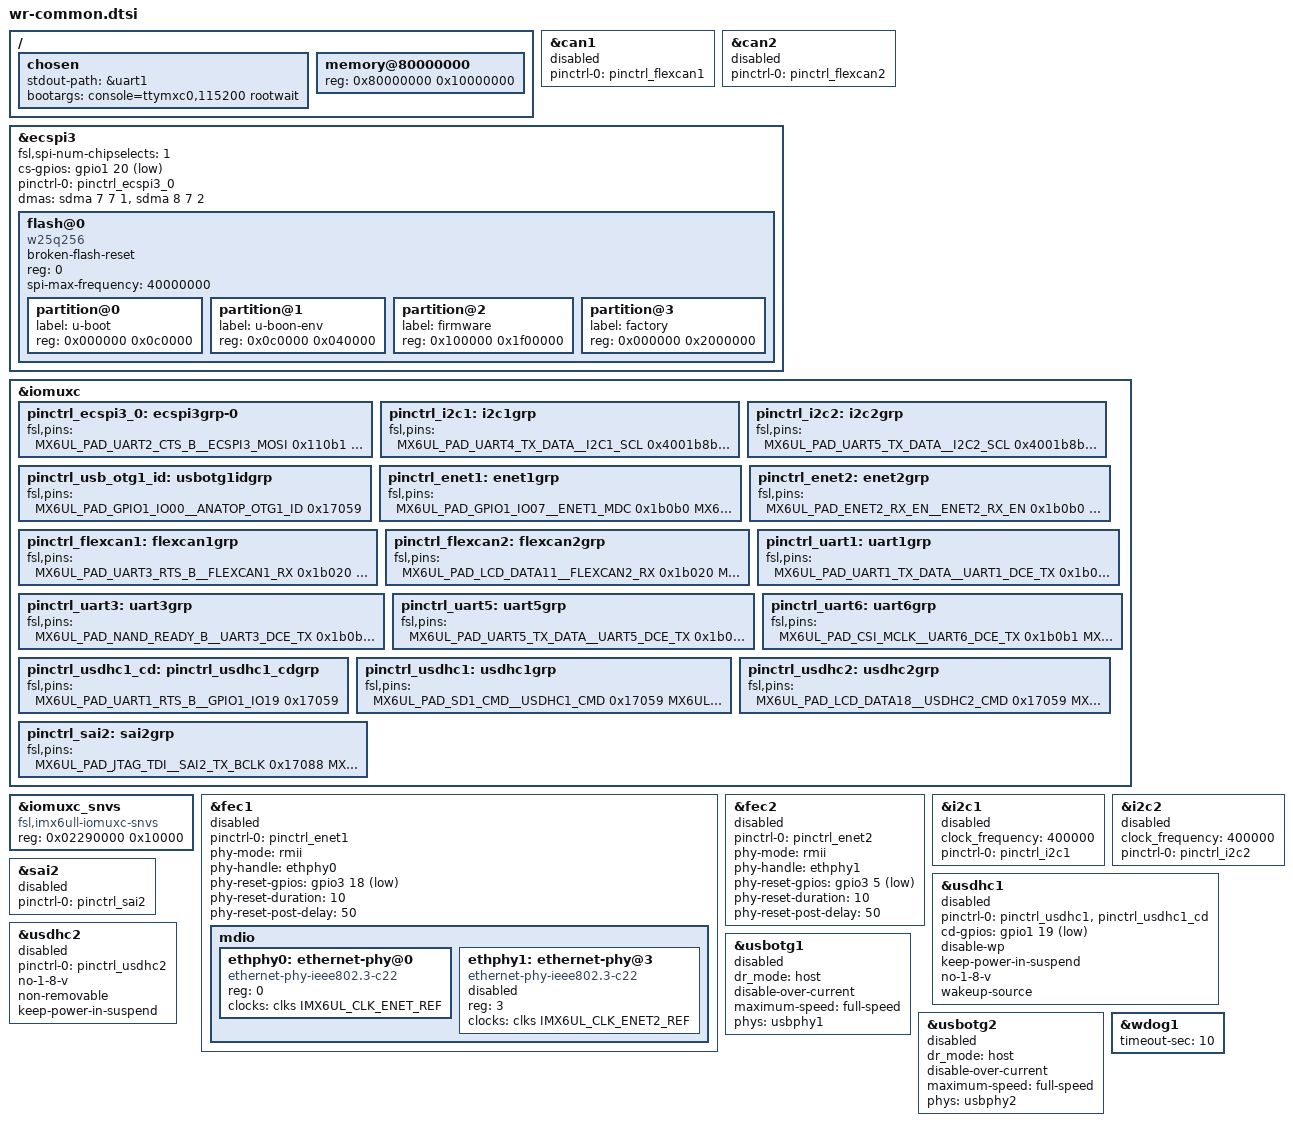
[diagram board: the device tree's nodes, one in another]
// SPDX-License-Identifier: GPL-2.0-only
/*
 * Device Tree Source for WirelessRoad Boards
 */


#include <dt-bindings/input/input.h>
#include "imx6ull.dtsi"

/ {
    chosen {
		stdout-path = &uart1;
		bootargs = "console=ttymxc0,115200 rootwait";
	};

    memory@80000000 {
        device_type = "memory";
		reg = <0x80000000 0x10000000>;
	};
};

&can1 {
	pinctrl-names = "default";
	pinctrl-0 = <&pinctrl_flexcan1>;
	status = "disabled";
};

&can2 {
	pinctrl-names = "default";
	pinctrl-0 = <&pinctrl_flexcan2>;
	status = "disabled";
};

// Do we really need this?
// &clks {
// 	assigned-clocks = <&clks IMX6UL_CLK_PLL4_AUDIO_DIV>;
// 	assigned-clock-rates = <786432000>;
// };

&ecspi3 {
	fsl,spi-num-chipselects = <1>;
	cs-gpios = <&gpio1 20 GPIO_ACTIVE_LOW>;
	pinctrl-names = "default";
	pinctrl-0 = <&pinctrl_ecspi3_0>;
	status = "okay";
	dma-names = "rx", "tx";
	dmas = <&sdma 7 7 1>, <&sdma 8 7 2>;

	flash@0 {
		#address-cells = <1>;
		#size-cells = <1>;
		compatible = "w25q256", "jedec,spi-nor";
		broken-flash-reset;
		reg = <0>;
		spi-max-frequency = <40000000>;
		status = "okay";

		partition@0 {
			label = "u-boot";
			reg = <0x000000 0x0c0000>;
		};

		partition@1 {
			label = "u-boon-env";
			reg = <0x0c0000 0x040000>;
		};

		partition@2 {
			label = "firmware";
			reg = <0x100000 0x1f00000>;
		};

		partition@3 {
			label = "factory";
			reg = <0x000000 0x2000000>;
		};
	};
};

&iomuxc {
	pinctrl_ecspi3_0: ecspi3grp-0 {
		fsl,pins = <
			MX6UL_PAD_UART2_CTS_B__ECSPI3_MOSI	0x110b1
			MX6UL_PAD_UART2_RTS_B__ECSPI3_MISO	0x110b1
			MX6UL_PAD_UART2_RX_DATA__ECSPI3_SCLK	0x110b1
			MX6UL_PAD_UART2_TX_DATA__GPIO1_IO20	0x10b0
		>;
	};

	pinctrl_i2c1: i2c1grp {
		fsl,pins = <
			MX6UL_PAD_UART4_TX_DATA__I2C1_SCL	0x4001b8b0
			MX6UL_PAD_UART4_RX_DATA__I2C1_SDA	0x4001b8b0
		>;
	};

	pinctrl_i2c2: i2c2grp {
		fsl,pins = <
			MX6UL_PAD_UART5_TX_DATA__I2C2_SCL		0x4001b8b0
			MX6UL_PAD_UART5_RX_DATA__I2C2_SDA		0x4001b8b0
		>;
	};

	pinctrl_usb_otg1_id: usbotg1idgrp {
		fsl,pins = <
			MX6UL_PAD_GPIO1_IO00__ANATOP_OTG1_ID	0x17059
		>;
	};
	
	pinctrl_enet1: enet1grp {
		fsl,pins = <
			MX6UL_PAD_GPIO1_IO07__ENET1_MDC         0x1b0b0
			MX6UL_PAD_GPIO1_IO06__ENET1_MDIO	0x1b0b0
			MX6UL_PAD_ENET1_RX_EN__ENET1_RX_EN	0x1b0b0
			MX6UL_PAD_ENET1_RX_ER__ENET1_RX_ER	0x1b0b0
			MX6UL_PAD_ENET1_RX_DATA0__ENET1_RDATA00	0x1b0b0
			MX6UL_PAD_ENET1_RX_DATA1__ENET1_RDATA01	0x1b0b0
			MX6UL_PAD_ENET1_TX_EN__ENET1_TX_EN	0x1b0b0
			MX6UL_PAD_ENET1_TX_DATA0__ENET1_TDATA00	0x1b0b0
			MX6UL_PAD_ENET1_TX_DATA1__ENET1_TDATA01	0x1b0b0
			MX6UL_PAD_ENET1_TX_CLK__ENET1_REF_CLK1	0x4001b031
		>;
	};

	pinctrl_enet2: enet2grp {
		fsl,pins = <
			MX6UL_PAD_ENET2_RX_EN__ENET2_RX_EN      0x1b0b0
			MX6UL_PAD_ENET2_RX_ER__ENET2_RX_ER      0x1b0b0
			MX6UL_PAD_ENET2_RX_DATA0__ENET2_RDATA00 0x1b0b0
			MX6UL_PAD_ENET2_RX_DATA1__ENET2_RDATA01 0x1b0b0
			MX6UL_PAD_ENET2_TX_EN__ENET2_TX_EN      0x1b0b0
			MX6UL_PAD_ENET2_TX_DATA0__ENET2_TDATA00 0x1b0b0
			MX6UL_PAD_ENET2_TX_DATA1__ENET2_TDATA01 0x1b0b0
			MX6UL_PAD_ENET2_TX_CLK__ENET2_REF_CLK2  0x4001b031
		>;
	};

	pinctrl_flexcan1: flexcan1grp{
		fsl,pins = <
			MX6UL_PAD_UART3_RTS_B__FLEXCAN1_RX	0x1b020
			MX6UL_PAD_UART3_CTS_B__FLEXCAN1_TX	0x1b020
		>;
	};

	pinctrl_flexcan2: flexcan2grp{
		fsl,pins = <
			MX6UL_PAD_LCD_DATA11__FLEXCAN2_RX      0x1b020
			MX6UL_PAD_LCD_DATA10__FLEXCAN2_TX      0x1b020
		>;
	};

	pinctrl_uart1: uart1grp {
		fsl,pins = <
			MX6UL_PAD_UART1_TX_DATA__UART1_DCE_TX 0x1b0b1
			MX6UL_PAD_UART1_RX_DATA__UART1_DCE_RX 0x1b0b1
		>;
	};

	pinctrl_uart3: uart3grp {
		fsl,pins = <
			MX6UL_PAD_NAND_READY_B__UART3_DCE_TX 0x1b0b1
			MX6UL_PAD_NAND_CE0_B__UART3_DCE_RX   0x1b0b1
		>;
	};

	pinctrl_uart5: uart5grp {
		fsl,pins = <
			MX6UL_PAD_UART5_TX_DATA__UART5_DCE_TX 0x1b0b1
			MX6UL_PAD_UART5_RX_DATA__UART5_DCE_RX 0x1b0b1
		>;
	};

	pinctrl_uart6: uart6grp {
		fsl,pins = <
			MX6UL_PAD_CSI_MCLK__UART6_DCE_TX   0x1b0b1
			MX6UL_PAD_CSI_PIXCLK__UART6_DCE_RX 0x1b0b1
		>;
	};

	pinctrl_usdhc1_cd: pinctrl_usdhc1_cdgrp {
		fsl,pins = <
			MX6UL_PAD_UART1_RTS_B__GPIO1_IO19	0x17059 /* SD1 CD */
		>;
	};

	pinctrl_usdhc1: usdhc1grp {
		fsl,pins = <
			MX6UL_PAD_SD1_CMD__USDHC1_CMD		0x17059
			MX6UL_PAD_SD1_CLK__USDHC1_CLK		0x10071
			MX6UL_PAD_SD1_DATA0__USDHC1_DATA0	0x17059
			MX6UL_PAD_SD1_DATA1__USDHC1_DATA1	0x17059
			MX6UL_PAD_SD1_DATA2__USDHC1_DATA2	0x17059
			MX6UL_PAD_SD1_DATA3__USDHC1_DATA3	0x17059
		>;
	};
	
	pinctrl_usdhc2: usdhc2grp {
		fsl,pins = <
			MX6UL_PAD_LCD_DATA18__USDHC2_CMD        0x17059
			MX6UL_PAD_LCD_DATA19__USDHC2_CLK        0x10071
			MX6UL_PAD_LCD_DATA20__USDHC2_DATA0      0x17059
			MX6UL_PAD_LCD_DATA21__USDHC2_DATA1      0x17059
			MX6UL_PAD_LCD_DATA22__USDHC2_DATA2      0x17059
			MX6UL_PAD_LCD_DATA23__USDHC2_DATA3      0x17059
		>;
	};

	pinctrl_sai2: sai2grp {
		fsl,pins = <
			MX6UL_PAD_JTAG_TDI__SAI2_TX_BCLK    0x17088
			MX6UL_PAD_JTAG_TDO__SAI2_TX_SYNC    0x17088
			MX6UL_PAD_JTAG_TRST_B__SAI2_TX_DATA 0x11088
			MX6UL_PAD_JTAG_TCK__SAI2_RX_DATA    0x11088
			MX6UL_PAD_JTAG_TMS__SAI2_MCLK       0x17088
		>;
	};
};

&iomuxc_snvs {
	compatible = "fsl,imx6ull-iomuxc-snvs";
	reg = <0x02290000 0x10000>;
	pinctrl-names = "default_snvs";
};

&fec1 {
	pinctrl-names = "default";
	pinctrl-0 = <&pinctrl_enet1>;
	phy-mode = "rmii";
	phy-handle = <&ethphy0>;
	phy-reset-gpios = <&gpio3 18 GPIO_ACTIVE_LOW>;
	phy-reset-duration = <10>;
	phy-reset-post-delay = <50>;
	status = "disabled";
	mdio {
		#address-cells = <1>;
		#size-cells = <0>;

		ethphy0: ethernet-phy@0 {
			compatible = "ethernet-phy-ieee802.3-c22";
			reg = <0>;
			clocks = <&clks IMX6UL_CLK_ENET_REF>;
			clock-names = "rmii-ref";
		};
		ethphy1: ethernet-phy@3 {
			compatible = "ethernet-phy-ieee802.3-c22";
			reg = <3>;
			clocks = <&clks IMX6UL_CLK_ENET2_REF>;
			clock-names = "rmii-ref";
			status = "disabled";
		};
	};
};

&fec2 {
	pinctrl-names = "default";
	pinctrl-0 = <&pinctrl_enet2>;
	phy-mode = "rmii";
	phy-handle = <&ethphy1>;
	phy-reset-gpios = <&gpio3 5 GPIO_ACTIVE_LOW>;
	phy-reset-duration = <10>;
	phy-reset-post-delay = <50>;
	status = "disabled";
};

&i2c1 {
	clock_frequency = <400000>;
	pinctrl-names = "default";
	pinctrl-0 = <&pinctrl_i2c1>;
	status = "disabled";
};

&i2c2 {
	clock_frequency = <400000>;
	pinctrl-names = "default";
	pinctrl-0 = <&pinctrl_i2c2>;
	status = "disabled";
};


&sai2 {
	pinctrl-names = "default";
	pinctrl-0 = <&pinctrl_sai2>;
	// assigned-clocks = <&clks IMX6UL_CLK_SAI2_SEL>,
	// 		  <&clks IMX6UL_CLK_SAI2>;
	// assigned-clock-parents = <&clks IMX6UL_CLK_PLL4_AUDIO_DIV>;
	// assigned-clock-rates = <0>, <24000000>;
	status = "disabled";
};

&usdhc1 {
	pinctrl-names = "default";
	pinctrl-0 = <&pinctrl_usdhc1 &pinctrl_usdhc1_cd>;
	cd-gpios = <&gpio1 19 GPIO_ACTIVE_LOW>;
	disable-wp;
	keep-power-in-suspend;
	no-1-8-v;
	wakeup-source;
	status = "disabled";
};

&usdhc2 {  /* Wifi SDIO */
	pinctrl-names = "default";
	pinctrl-0 = <&pinctrl_usdhc2>;
	no-1-8-v;
	non-removable;
	keep-power-in-suspend;
	// wakeup-source;
	status = "disabled";
};

&usbotg1 {
	dr_mode = "host";
	disable-over-current;
	maximum-speed = "full-speed";
	// external-vbus-divider;
	phys = <&usbphy1>;
	phy-names = "usb-phy";
	status = "disabled";
};

&usbotg2 {
	dr_mode = "host";
	disable-over-current;
	maximum-speed = "full-speed";
	// external-vbus-divider;
	phys = <&usbphy2>;
	phy-names = "usb-phy";
	status = "disabled";
};

&wdog1 {
	timeout-sec = <10>;
};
